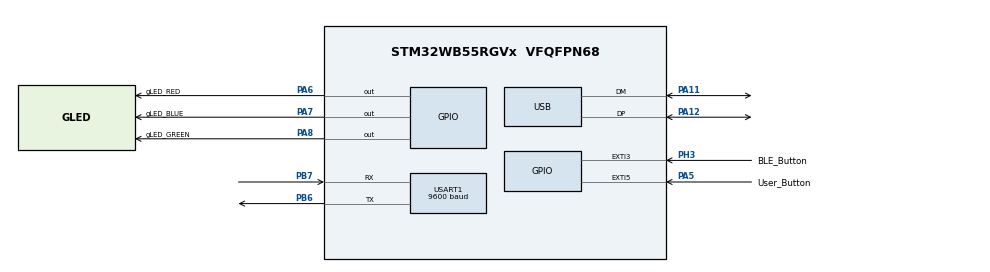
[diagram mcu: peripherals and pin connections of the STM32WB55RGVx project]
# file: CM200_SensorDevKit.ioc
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Dma.Request0=USART1_TX
Dma.USART1_TX.0.Direction=DMA_MEMORY_TO_PERIPH
Dma.USART1_TX.0.EventEnable=DISABLE
Dma.USART1_TX.0.Instance=DMA1_Channel1
Dma.USART1_TX.0.MemDataAlignment=DMA_MDATAALIGN_BYTE
Dma.USART1_TX.0.MemInc=DMA_MINC_ENABLE
Dma.USART1_TX.0.Mode=DMA_NORMAL
Dma.USART1_TX.0.PeriphDataAlignment=DMA_PDATAALIGN_BYTE
Dma.USART1_TX.0.PeriphInc=DMA_PINC_DISABLE
Dma.USART1_TX.0.Polarity=HAL_DMAMUX_REQ_GEN_RISING
Dma.USART1_TX.0.Priority=DMA_PRIORITY_LOW
Dma.USART1_TX.0.RequestNumber=1
Dma.USART1_TX.0.SignalID=NONE
Dma.USART1_TX.0.SyncEnable=DISABLE
Dma.USART1_TX.0.SyncPolarity=HAL_DMAMUX_SYNC_NO_EVENT
Dma.USART1_TX.0.SyncRequestNumber=1
Dma.USART1_TX.0.SyncSignalID=NONE
Mcu.Family=STM32WB
Mcu.Name=STM32WB55RGVx
Mcu.Package=VFQFPN68
NVIC.DMA1_Channel1_IRQn=true\:0\:0\:false\:false\:true\:false\:true\:true
NVIC.HSEM_IRQn=true\:0\:0\:false\:false\:true\:false\:true\:true
NVIC.IPCC_C1_RX_IRQn=true\:0\:0\:false\:false\:true\:true\:true\:true
NVIC.IPCC_C1_TX_IRQn=true\:0\:0\:false\:false\:true\:true\:true\:true
NVIC.PriorityGroup=NVIC_PRIORITYGROUP_4
NVIC.RTC_WKUP_IRQn=true\:0\:0\:false\:false\:true\:true\:true\:true
NVIC.TIM2_IRQn=true\:0\:0\:false\:false\:true\:true\:true\:true
NVIC.USART1_IRQn=true\:0\:0\:false\:false\:true\:true\:true\:true
NVIC.USB_LP_IRQn=true\:0\:0\:false\:false\:true\:false\:true\:true
OSC_IN.Mode=HSE-External-Oscillator
OSC_IN.Signal=RCC_OSC_IN
OSC_OUT.Mode=HSE-External-Oscillator
OSC_OUT.Signal=RCC_OSC_OUT
PA11.Mode=Device
PA11.Signal=USB_DM
PA12.Mode=Device
PA12.Signal=USB_DP
PA5.GPIO_Label=User_Button
PA5.GPIO_ModeDefaultEXTI=GPIO_MODE_IT_FALLING
PA5.GPIO_PuPd=GPIO_PULLUP
PA5.Signal=GPXTI5
PA6.GPIO_Label=gLED_RED
PA6.PinState=GPIO_PIN_SET
PA6.Signal=GPIO_Output
PA7.GPIO_Label=gLED_BLUE
PA7.PinState=GPIO_PIN_SET
PA7.Signal=GPIO_Output
PA8.GPIO_Label=gLED_GREEN
PA8.PinState=GPIO_PIN_SET
PA8.Signal=GPIO_Output
PB6.Mode=Asynchronous
PB6.Signal=USART1_TX
PB7.Mode=Asynchronous
PB7.Signal=USART1_RX
PC14-OSC32_IN.Mode=LSE-External-Oscillator
PC14-OSC32_IN.Signal=RCC_OSC32_IN
PC15-OSC32_OUT.Mode=LSE-External-Oscillator
PC15-OSC32_OUT.Signal=RCC_OSC32_OUT
PH3-BOOT0.GPIO_Label=BLE_Button
PH3-BOOT0.GPIO_ModeDefaultEXTI=GPIO_MODE_IT_RISING
PH3-BOOT0.Signal=GPXTI3
ProjectManager.HeapSize=0x200
ProjectManager.StackSize=0x400
ProjectManager.TargetToolchain=STM32CubeIDE
RCC.ADCFreq_Value=48000000
RCC.AHB2CLKDivider=RCC_SYSCLK_DIV2
RCC.AHBFreq_Value=64000000
RCC.APB1Freq_Value=64000000
RCC.APB1TimFreq_Value=64000000
RCC.APB2Freq_Value=64000000
RCC.APB2TimFreq_Value=64000000
RCC.APB3Freq_Value=16000000
RCC.Cortex2_Div=SYSTICK_CLKSOURCE_HCLK_DIV8
RCC.CortexFreq_Value=64000000
RCC.HCLKFreq_Value=64000000
RCC.HSE_VALUE=32000000
RCC.HSI48_VALUE=48000000
RCC.HSI_VALUE=16000000
RCC.PLLN=32
RCC.PLLSAI1N=24
RCC.SYSCLKFreq_VALUE=64000000
RCC.SYSCLKSource=RCC_SYSCLKSOURCE_PLLCLK
RCC.USBFreq_Value=48000000
RCC.VCOOutputFreq_Value=128000000
RF1.Mode=RF1_Activate
RF1.Signal=RF_RF1
STM32_WPAN.AD_TYPE_COMPLETE_LOCAL_NAME=CM-200t
STM32_WPAN.AD_TYPE_COMPLETE_LOCAL_NAME_LENGTH=8
STM32_WPAN.CUSTOM_P2P_SERVER=Disabled
STM32_WPAN.CUSTOM_TEMPLATE=Enabled
STM32_WPAN.INCLUDE_AD_TYPE_COMPLETE_LOCAL_NAME=1
STM32_WPAN.INCLUDE_AD_TYPE_TX_POWER_LEVEL=1
STM32_WPAN.LOCAL_NAME=CM-200
STM32_WPAN.LOCAL_NAME_FORMATTED=,'C','M','-','2','0','0'
STM32_WPAN.NUMBER_OF_SERVICES=1
STM32_WPAN.SERVICE1_CHAR1_ATTR_PERMISSION_AUTHEN_READ=\ 
STM32_WPAN.SERVICE1_CHAR1_ATTR_PERMISSION_AUTHOR_WRITE=\ 
STM32_WPAN.SERVICE1_CHAR1_GATT_NOTIFY_READ_REQ_AND_WAIT_FOR_APPL_RESP=\ 
STM32_WPAN.SERVICE1_CHAR1_GATT_NOTIFY_WRITE_REQ_AND_WAIT_FOR_APPL_RESP=\ 
STM32_WPAN.SERVICE1_CHAR1_LENGTH_CHARACTERISTIC=CHAR_VALUE_LEN_VARIABLE
STM32_WPAN.SERVICE1_CHAR1_LONG_NAME=CM200_UART_WRITE
STM32_WPAN.SERVICE1_CHAR1_PROP_READ=CHAR_PROP_READ
STM32_WPAN.SERVICE1_CHAR1_PROP_WRITE_WITHOUT_RESP=CHAR_PROP_WRITE_WITHOUT_RESP
STM32_WPAN.SERVICE1_CHAR1_SHORT_NAME=WRITE
STM32_WPAN.SERVICE1_CHAR1_UUID=FE 61
STM32_WPAN.SERVICE1_CHAR1_VALUE_LENGTH=32
STM32_WPAN.SERVICE1_CHAR2_ATTR_PERMISSION_AUTHOR_READ=\ 
STM32_WPAN.SERVICE1_CHAR2_GATT_NOTIFY_READ_REQ_AND_WAIT_FOR_APPL_RESP=\ 
STM32_WPAN.SERVICE1_CHAR2_GATT_NOTIFY_WRITE_REQ_AND_WAIT_FOR_APPL_RESP=\ 
STM32_WPAN.SERVICE1_CHAR2_LENGTH_CHARACTERISTIC=CHAR_VALUE_LEN_VARIABLE
STM32_WPAN.SERVICE1_CHAR2_LONG_NAME=CM200_UART_READ
STM32_WPAN.SERVICE1_CHAR2_PROP_NOTIFY=CHAR_PROP_NOTIFY
STM32_WPAN.SERVICE1_CHAR2_PROP_READ=CHAR_PROP_READ
STM32_WPAN.SERVICE1_CHAR2_SHORT_NAME=READ
STM32_WPAN.SERVICE1_CHAR2_UUID=FE 62
STM32_WPAN.SERVICE1_CHAR2_VALUE_LENGTH=32
STM32_WPAN.SERVICE1_LONG_NAME=CM200_SensorDevKit
STM32_WPAN.SERVICE1_NUMBER_OF_CHARACTERISTICS=2
STM32_WPAN.SERVICE1_SHORT_NAME=CM200
STM32_WPAN.SERVICE1_UUID=FE 60
TIM2.Period=5000
TIM2.Prescaler=6399
USART1.BaudRate=9600
USART1.VirtualMode-Asynchronous=VM_ASYNC
USB_DEVICE.CLASS_NAME_FS=CDC
USB_DEVICE.MANUFACTURER_STRING=CO2Meter, Inc.
USB_DEVICE.PRODUCT_STRING_CDC_FS=CM-200 SensorDevKit
USB_DEVICE.VirtualMode=Cdc
USB_DEVICE.VirtualModeFS=Cdc_FS
VP_HSEM_VS_HSEM.Mode=HSEM_Activate
VP_IPCC_VS_IPCC.Mode=IPCC_Activate
VP_MEMORYMAP_VS_MEMORYMAP.Mode=CurAppReg
VP_RTC_VS_RTC_Activate.Mode=RTC_Enabled
VP_RTC_VS_RTC_WakeUp_intern.Mode=WakeUp
VP_SEQUENCER_VS_SEQUENCER.Mode=SEQUENCER_Enabled
VP_STM32_WPAN_VS_BLE_HOST.Mode=STM32_WPAN_Enabled
VP_TIM2_VS_ClockSourceINT.Mode=Internal
VP_TINY_LPM_VS_TINY_LPM.Mode=TINY_LPM_Enabled
VP_USB_DEVICE_VS_USB_DEVICE_CDC_FS.Mode=CDC_FS
board=custom

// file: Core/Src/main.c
/* USER CODE BEGIN Header */
/**
  ******************************************************************************
  * @file           : main.c
  * @brief          : Main program body
  ******************************************************************************
  * @attention
  *
  * Copyright (c) 2024 STMicroelectronics.
  * All rights reserved.
  *
  * This software is licensed under terms that can be found in the LICENSE file
  * in the root directory of this software component.
  * If no LICENSE file comes with this software, it is provided AS-IS.
  *
  ******************************************************************************
  */
/* USER CODE END Header */
#include "main.h"
#include "usb_device.h"

/* USER CODE BEGIN Includes */
#include "uart_ifce.h"
/* USER CODE END Includes */

IPCC_HandleTypeDef hipcc;

RTC_HandleTypeDef hrtc;

TIM_HandleTypeDef htim2;

UART_HandleTypeDef huart1;
DMA_HandleTypeDef hdma_usart1_tx;

void SystemClock_Config(void);
void PeriphCommonClock_Config(void);
static void MX_GPIO_Init(void);
static void MX_DMA_Init(void);
static void MX_USART1_UART_Init(void);
static void MX_TIM2_Init(void);
static void MX_IPCC_Init(void);
static void MX_RTC_Init(void);
static void MX_RF_Init(void);

int main(void)
{

  /* MCU Configuration--------------------------------------------------------*/

  /* Reset of all peripherals, Initializes the Flash interface and the Systick. */
  HAL_Init();
  /* Config code for STM32_WPAN (HSE Tuning must be done before system clock configuration) */
  MX_APPE_Config();

  /* Configure the system clock */
  SystemClock_Config();

/* Configure the peripherals common clocks */
  PeriphCommonClock_Config();

  /* IPCC initialisation */
  MX_IPCC_Init();

  /* Initialize all configured peripherals */
  MX_GPIO_Init();
  MX_DMA_Init();
  MX_USB_Device_Init();
  MX_USART1_UART_Init();
  MX_TIM2_Init();
  MX_RTC_Init();
  MX_RF_Init();
  /* USER CODE BEGIN 2 */
  if (HAL_TIM_Base_Start_IT(&htim2) != HAL_OK)
  {
    /* Starting Error */
    Error_Handler();
  }

  uart_ifce_init();
  LL_HSEM_1StepLock( HSEM, 5 );
  /* USER CODE END 2 */

  /* Init code for STM32_WPAN */
  MX_APPE_Init();

  /* Infinite loop */
  while (1)
  {
    MX_APPE_Process();

  }
}

void SystemClock_Config(void)
{
  RCC_OscInitTypeDef RCC_OscInitStruct = {0};
  RCC_ClkInitTypeDef RCC_ClkInitStruct = {0};

  /** Configure LSE Drive Capability
  */
  HAL_PWR_EnableBkUpAccess();
  __HAL_RCC_LSEDRIVE_CONFIG(RCC_LSEDRIVE_MEDIUMHIGH);

  /** Configure the main internal regulator output voltage
  */
  __HAL_PWR_VOLTAGESCALING_CONFIG(PWR_REGULATOR_VOLTAGE_SCALE1);

  /** Initializes the RCC Oscillators according to the specified parameters
  * in the RCC_OscInitTypeDef structure.
  */
  RCC_OscInitStruct.OscillatorType = RCC_OSCILLATORTYPE_HSI|RCC_OSCILLATORTYPE_LSI1
                              |RCC_OSCILLATORTYPE_HSE|RCC_OSCILLATORTYPE_LSE
                              |RCC_OSCILLATORTYPE_MSI;
  RCC_OscInitStruct.HSEState = RCC_HSE_ON;
  RCC_OscInitStruct.LSEState = RCC_LSE_ON;
  RCC_OscInitStruct.HSIState = RCC_HSI_ON;
  RCC_OscInitStruct.MSIState = RCC_MSI_ON;
  RCC_OscInitStruct.HSICalibrationValue = RCC_HSICALIBRATION_DEFAULT;
  RCC_OscInitStruct.MSICalibrationValue = RCC_MSICALIBRATION_DEFAULT;
  RCC_OscInitStruct.MSIClockRange = RCC_MSIRANGE_6;
  RCC_OscInitStruct.LSIState = RCC_LSI_ON;
  RCC_OscInitStruct.PLL.PLLState = RCC_PLL_ON;
  RCC_OscInitStruct.PLL.PLLSource = RCC_PLLSOURCE_MSI;
  RCC_OscInitStruct.PLL.PLLM = RCC_PLLM_DIV1;
  RCC_OscInitStruct.PLL.PLLN = 32;
  RCC_OscInitStruct.PLL.PLLP = RCC_PLLP_DIV2;
  RCC_OscInitStruct.PLL.PLLR = RCC_PLLR_DIV2;
  RCC_OscInitStruct.PLL.PLLQ = RCC_PLLQ_DIV2;
  if (HAL_RCC_OscConfig(&RCC_OscInitStruct) != HAL_OK)
  {
    Error_Handler();
  }

  /** Configure the SYSCLKSource, HCLK, PCLK1 and PCLK2 clocks dividers
  */
  RCC_ClkInitStruct.ClockType = RCC_CLOCKTYPE_HCLK4|RCC_CLOCKTYPE_HCLK2
                              |RCC_CLOCKTYPE_HCLK|RCC_CLOCKTYPE_SYSCLK
                              |RCC_CLOCKTYPE_PCLK1|RCC_CLOCKTYPE_PCLK2;
  RCC_ClkInitStruct.SYSCLKSource = RCC_SYSCLKSOURCE_PLLCLK;
  RCC_ClkInitStruct.AHBCLKDivider = RCC_SYSCLK_DIV1;
  RCC_ClkInitStruct.APB1CLKDivider = RCC_HCLK_DIV1;
  RCC_ClkInitStruct.APB2CLKDivider = RCC_HCLK_DIV1;
  RCC_ClkInitStruct.AHBCLK2Divider = RCC_SYSCLK_DIV2;
  RCC_ClkInitStruct.AHBCLK4Divider = RCC_SYSCLK_DIV1;

  if (HAL_RCC_ClockConfig(&RCC_ClkInitStruct, FLASH_LATENCY_3) != HAL_OK)
  {
    Error_Handler();
  }

  /** Enable MSI Auto calibration
  */
  HAL_RCCEx_EnableMSIPLLMode();
}

void PeriphCommonClock_Config(void)
{
  RCC_PeriphCLKInitTypeDef PeriphClkInitStruct = {0};

  /** Initializes the peripherals clock
  */
  PeriphClkInitStruct.PeriphClockSelection = RCC_PERIPHCLK_SMPS|RCC_PERIPHCLK_RFWAKEUP;
  PeriphClkInitStruct.RFWakeUpClockSelection = RCC_RFWKPCLKSOURCE_HSE_DIV1024;
  PeriphClkInitStruct.SmpsClockSelection = RCC_SMPSCLKSOURCE_HSI;
  PeriphClkInitStruct.SmpsDivSelection = RCC_SMPSCLKDIV_RANGE1;

  if (HAL_RCCEx_PeriphCLKConfig(&PeriphClkInitStruct) != HAL_OK)
  {
    Error_Handler();
  }
}

static void MX_IPCC_Init(void)
{

  hipcc.Instance = IPCC;
  if (HAL_IPCC_Init(&hipcc) != HAL_OK)
  {
    Error_Handler();
  }

}

static void MX_RF_Init(void)
{

}

static void MX_RTC_Init(void)
{

  /** Initialize RTC Only
  */
  hrtc.Instance = RTC;
  hrtc.Init.HourFormat = RTC_HOURFORMAT_24;
  hrtc.Init.AsynchPrediv = CFG_RTC_ASYNCH_PRESCALER;
  hrtc.Init.SynchPrediv = CFG_RTC_SYNCH_PRESCALER;
  hrtc.Init.OutPut = RTC_OUTPUT_DISABLE;
  hrtc.Init.OutPutPolarity = RTC_OUTPUT_POLARITY_HIGH;
  hrtc.Init.OutPutType = RTC_OUTPUT_TYPE_OPENDRAIN;
  hrtc.Init.OutPutRemap = RTC_OUTPUT_REMAP_NONE;
  if (HAL_RTC_Init(&hrtc) != HAL_OK)
  {
    Error_Handler();
  }

  /** Enable the WakeUp
  */
  if (HAL_RTCEx_SetWakeUpTimer_IT(&hrtc, 0, RTC_WAKEUPCLOCK_RTCCLK_DIV16) != HAL_OK)
  {
    Error_Handler();
  }

}

static void MX_TIM2_Init(void)
{

  TIM_ClockConfigTypeDef sClockSourceConfig = {0};
  TIM_MasterConfigTypeDef sMasterConfig = {0};

  htim2.Instance = TIM2;
  htim2.Init.Prescaler = 6399;
  htim2.Init.CounterMode = TIM_COUNTERMODE_UP;
  htim2.Init.Period = 5000;
  htim2.Init.ClockDivision = TIM_CLOCKDIVISION_DIV1;
  htim2.Init.AutoReloadPreload = TIM_AUTORELOAD_PRELOAD_DISABLE;
  if (HAL_TIM_Base_Init(&htim2) != HAL_OK)
  {
    Error_Handler();
  }
  sClockSourceConfig.ClockSource = TIM_CLOCKSOURCE_INTERNAL;
  if (HAL_TIM_ConfigClockSource(&htim2, &sClockSourceConfig) != HAL_OK)
  {
    Error_Handler();
  }
  sMasterConfig.MasterOutputTrigger = TIM_TRGO_RESET;
  sMasterConfig.MasterSlaveMode = TIM_MASTERSLAVEMODE_DISABLE;
  if (HAL_TIMEx_MasterConfigSynchronization(&htim2, &sMasterConfig) != HAL_OK)
  {
    Error_Handler();
  }

}

static void MX_USART1_UART_Init(void)
{

  huart1.Instance = USART1;
  huart1.Init.BaudRate = 9600;
  huart1.Init.WordLength = UART_WORDLENGTH_8B;
  huart1.Init.StopBits = UART_STOPBITS_1;
  huart1.Init.Parity = UART_PARITY_NONE;
  huart1.Init.Mode = UART_MODE_TX_RX;
  huart1.Init.HwFlowCtl = UART_HWCONTROL_NONE;
  huart1.Init.OverSampling = UART_OVERSAMPLING_16;
  huart1.Init.OneBitSampling = UART_ONE_BIT_SAMPLE_DISABLE;
  huart1.Init.ClockPrescaler = UART_PRESCALER_DIV1;
  huart1.AdvancedInit.AdvFeatureInit = UART_ADVFEATURE_NO_INIT;
  if (HAL_UART_Init(&huart1) != HAL_OK)
  {
    Error_Handler();
  }
  if (HAL_UARTEx_SetTxFifoThreshold(&huart1, UART_TXFIFO_THRESHOLD_1_8) != HAL_OK)
  {
    Error_Handler();
  }
  if (HAL_UARTEx_SetRxFifoThreshold(&huart1, UART_RXFIFO_THRESHOLD_1_8) != HAL_OK)
  {
    Error_Handler();
  }
  if (HAL_UARTEx_DisableFifoMode(&huart1) != HAL_OK)
  {
    Error_Handler();
  }

}

static void MX_DMA_Init(void)
{

  /* DMA controller clock enable */
  __HAL_RCC_DMAMUX1_CLK_ENABLE();
  __HAL_RCC_DMA1_CLK_ENABLE();

  /* DMA interrupt init */
  /* DMA1_Channel1_IRQn interrupt configuration */
  HAL_NVIC_SetPriority(DMA1_Channel1_IRQn, 0, 0);
  HAL_NVIC_EnableIRQ(DMA1_Channel1_IRQn);

}

static void MX_GPIO_Init(void)
{
  GPIO_InitTypeDef GPIO_InitStruct = {0};

  /* GPIO Ports Clock Enable */
  __HAL_RCC_GPIOC_CLK_ENABLE();
  __HAL_RCC_GPIOH_CLK_ENABLE();
  __HAL_RCC_GPIOA_CLK_ENABLE();
  __HAL_RCC_GPIOB_CLK_ENABLE();

  /*Configure GPIO pin Output Level */
  HAL_GPIO_WritePin(GPIOA, gLED_RED_Pin|gLED_BLUE_Pin|gLED_GREEN_Pin, GPIO_PIN_SET);

  /*Configure GPIO pin : BLE_Button_Pin */
  GPIO_InitStruct.Pin = BLE_Button_Pin;
  GPIO_InitStruct.Mode = GPIO_MODE_IT_RISING;
  GPIO_InitStruct.Pull = GPIO_NOPULL;
  HAL_GPIO_Init(BLE_Button_GPIO_Port, &GPIO_InitStruct);

  /*Configure GPIO pin : User_Button_Pin */
  GPIO_InitStruct.Pin = User_Button_Pin;
  GPIO_InitStruct.Mode = GPIO_MODE_IT_FALLING;
  GPIO_InitStruct.Pull = GPIO_PULLUP;
  HAL_GPIO_Init(User_Button_GPIO_Port, &GPIO_InitStruct);

  /*Configure GPIO pins : gLED_RED_Pin gLED_BLUE_Pin gLED_GREEN_Pin */
  GPIO_InitStruct.Pin = gLED_RED_Pin|gLED_BLUE_Pin|gLED_GREEN_Pin;
  GPIO_InitStruct.Mode = GPIO_MODE_OUTPUT_PP;
  GPIO_InitStruct.Pull = GPIO_NOPULL;
  GPIO_InitStruct.Speed = GPIO_SPEED_FREQ_LOW;
  HAL_GPIO_Init(GPIOA, &GPIO_InitStruct);

}

void Error_Handler(void)
{
  __disable_irq();
  while (1)
  {
  }
}
